# iorx65n register map
Registers are 8-bit, access not given, no defined reset value unless marked. A register's access mark holds for its fields unless they carry their own. Addresses are absolute; registers are grouped by the start of their names; [hi:lo] are bit positions.

## SFR (part 6 of 7)
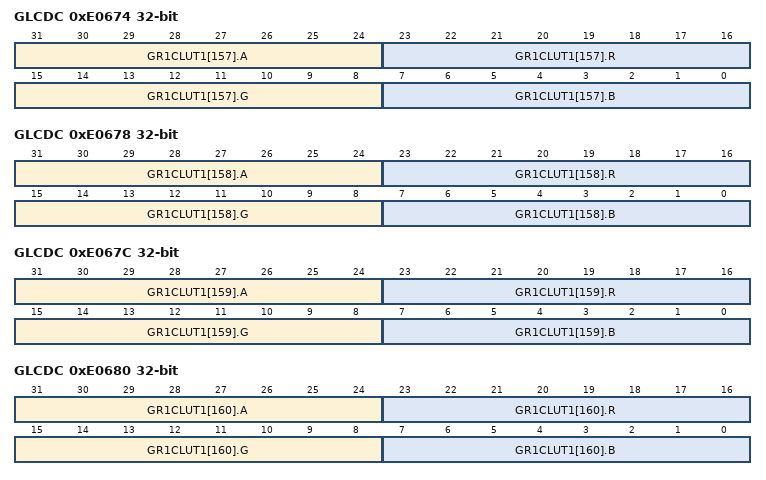
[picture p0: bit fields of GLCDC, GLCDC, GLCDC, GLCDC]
0xE0674 GLCDC 32-bit
  [31:24] GR1CLUT1[157].A, [23:16] GR1CLUT1[157].R, [15:8] GR1CLUT1[157].G, [7:0] GR1CLUT1[157].B
0xE0678 GLCDC 32-bit
  [31:24] GR1CLUT1[158].A, [23:16] GR1CLUT1[158].R, [15:8] GR1CLUT1[158].G, [7:0] GR1CLUT1[158].B
0xE067C GLCDC 32-bit
  [31:24] GR1CLUT1[159].A, [23:16] GR1CLUT1[159].R, [15:8] GR1CLUT1[159].G, [7:0] GR1CLUT1[159].B
0xE0680 GLCDC 32-bit
  [31:24] GR1CLUT1[160].A, [23:16] GR1CLUT1[160].R, [15:8] GR1CLUT1[160].G, [7:0] GR1CLUT1[160].B
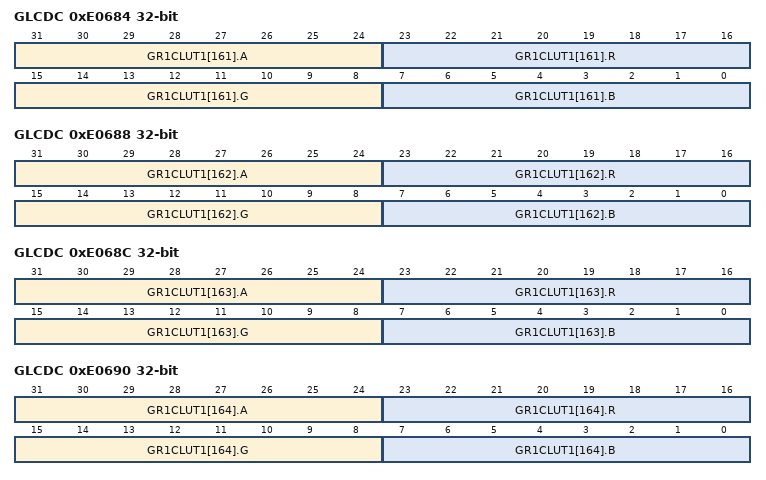
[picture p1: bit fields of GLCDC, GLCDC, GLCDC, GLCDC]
0xE0684 GLCDC 32-bit
  [31:24] GR1CLUT1[161].A, [23:16] GR1CLUT1[161].R, [15:8] GR1CLUT1[161].G, [7:0] GR1CLUT1[161].B
0xE0688 GLCDC 32-bit
  [31:24] GR1CLUT1[162].A, [23:16] GR1CLUT1[162].R, [15:8] GR1CLUT1[162].G, [7:0] GR1CLUT1[162].B
0xE068C GLCDC 32-bit
  [31:24] GR1CLUT1[163].A, [23:16] GR1CLUT1[163].R, [15:8] GR1CLUT1[163].G, [7:0] GR1CLUT1[163].B
0xE0690 GLCDC 32-bit
  [31:24] GR1CLUT1[164].A, [23:16] GR1CLUT1[164].R, [15:8] GR1CLUT1[164].G, [7:0] GR1CLUT1[164].B
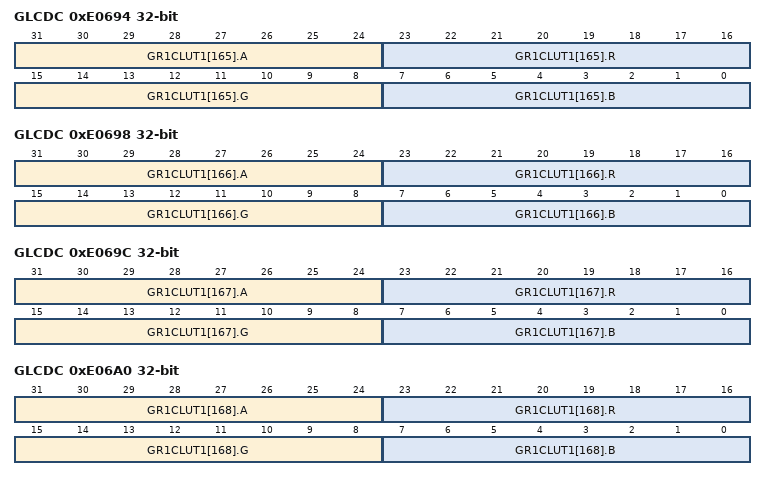
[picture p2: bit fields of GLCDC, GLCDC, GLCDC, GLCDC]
0xE0694 GLCDC 32-bit
  [31:24] GR1CLUT1[165].A, [23:16] GR1CLUT1[165].R, [15:8] GR1CLUT1[165].G, [7:0] GR1CLUT1[165].B
0xE0698 GLCDC 32-bit
  [31:24] GR1CLUT1[166].A, [23:16] GR1CLUT1[166].R, [15:8] GR1CLUT1[166].G, [7:0] GR1CLUT1[166].B
0xE069C GLCDC 32-bit
  [31:24] GR1CLUT1[167].A, [23:16] GR1CLUT1[167].R, [15:8] GR1CLUT1[167].G, [7:0] GR1CLUT1[167].B
0xE06A0 GLCDC 32-bit
  [31:24] GR1CLUT1[168].A, [23:16] GR1CLUT1[168].R, [15:8] GR1CLUT1[168].G, [7:0] GR1CLUT1[168].B
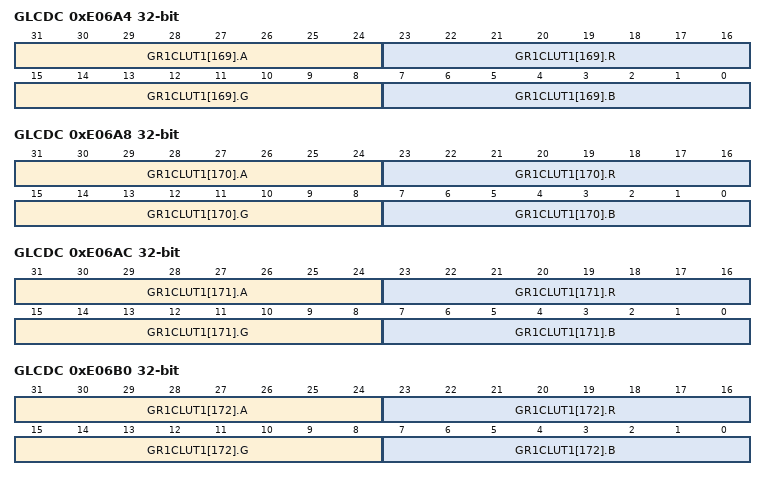
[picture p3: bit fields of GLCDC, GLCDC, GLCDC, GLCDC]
0xE06A4 GLCDC 32-bit
  [31:24] GR1CLUT1[169].A, [23:16] GR1CLUT1[169].R, [15:8] GR1CLUT1[169].G, [7:0] GR1CLUT1[169].B
0xE06A8 GLCDC 32-bit
  [31:24] GR1CLUT1[170].A, [23:16] GR1CLUT1[170].R, [15:8] GR1CLUT1[170].G, [7:0] GR1CLUT1[170].B
0xE06AC GLCDC 32-bit
  [31:24] GR1CLUT1[171].A, [23:16] GR1CLUT1[171].R, [15:8] GR1CLUT1[171].G, [7:0] GR1CLUT1[171].B
0xE06B0 GLCDC 32-bit
  [31:24] GR1CLUT1[172].A, [23:16] GR1CLUT1[172].R, [15:8] GR1CLUT1[172].G, [7:0] GR1CLUT1[172].B
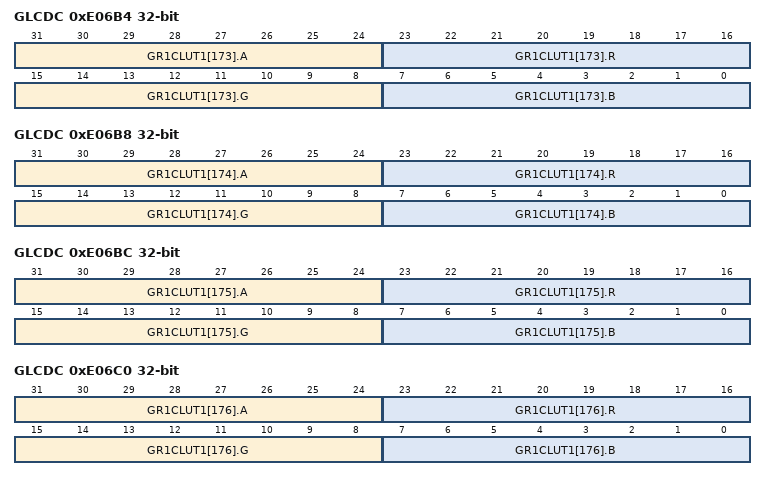
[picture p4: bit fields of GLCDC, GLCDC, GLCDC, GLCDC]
0xE06B4 GLCDC 32-bit
  [31:24] GR1CLUT1[173].A, [23:16] GR1CLUT1[173].R, [15:8] GR1CLUT1[173].G, [7:0] GR1CLUT1[173].B
0xE06B8 GLCDC 32-bit
  [31:24] GR1CLUT1[174].A, [23:16] GR1CLUT1[174].R, [15:8] GR1CLUT1[174].G, [7:0] GR1CLUT1[174].B
0xE06BC GLCDC 32-bit
  [31:24] GR1CLUT1[175].A, [23:16] GR1CLUT1[175].R, [15:8] GR1CLUT1[175].G, [7:0] GR1CLUT1[175].B
0xE06C0 GLCDC 32-bit
  [31:24] GR1CLUT1[176].A, [23:16] GR1CLUT1[176].R, [15:8] GR1CLUT1[176].G, [7:0] GR1CLUT1[176].B
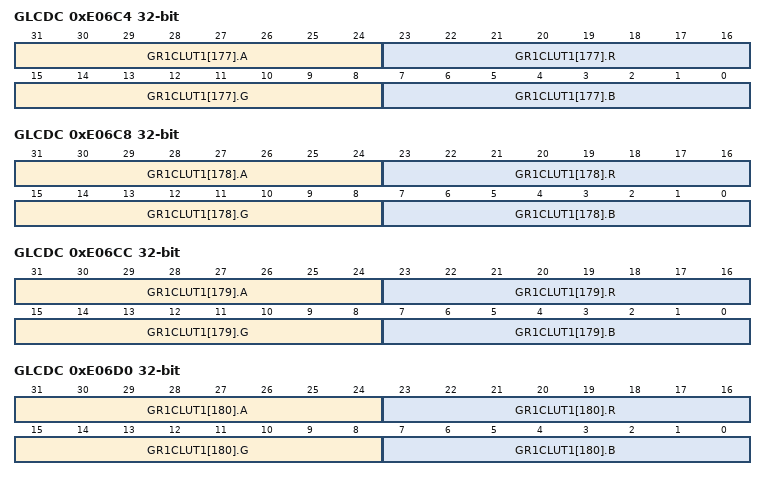
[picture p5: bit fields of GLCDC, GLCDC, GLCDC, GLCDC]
0xE06C4 GLCDC 32-bit
  [31:24] GR1CLUT1[177].A, [23:16] GR1CLUT1[177].R, [15:8] GR1CLUT1[177].G, [7:0] GR1CLUT1[177].B
0xE06C8 GLCDC 32-bit
  [31:24] GR1CLUT1[178].A, [23:16] GR1CLUT1[178].R, [15:8] GR1CLUT1[178].G, [7:0] GR1CLUT1[178].B
0xE06CC GLCDC 32-bit
  [31:24] GR1CLUT1[179].A, [23:16] GR1CLUT1[179].R, [15:8] GR1CLUT1[179].G, [7:0] GR1CLUT1[179].B
0xE06D0 GLCDC 32-bit
  [31:24] GR1CLUT1[180].A, [23:16] GR1CLUT1[180].R, [15:8] GR1CLUT1[180].G, [7:0] GR1CLUT1[180].B
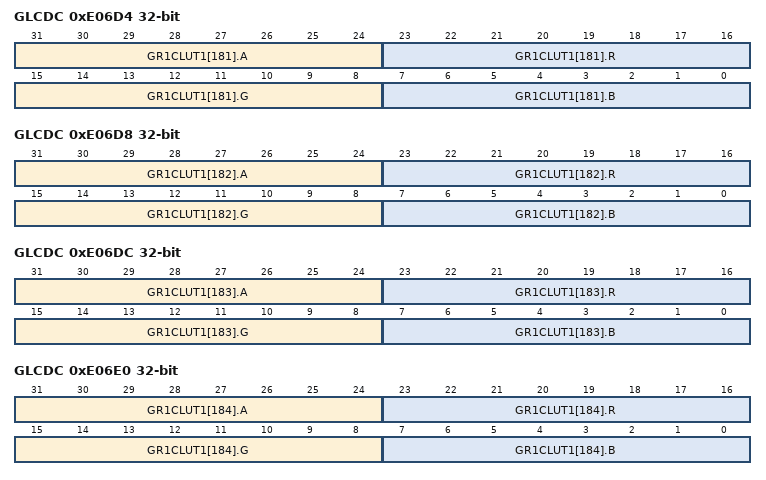
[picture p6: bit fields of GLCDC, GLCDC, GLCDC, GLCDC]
0xE06D4 GLCDC 32-bit
  [31:24] GR1CLUT1[181].A, [23:16] GR1CLUT1[181].R, [15:8] GR1CLUT1[181].G, [7:0] GR1CLUT1[181].B
0xE06D8 GLCDC 32-bit
  [31:24] GR1CLUT1[182].A, [23:16] GR1CLUT1[182].R, [15:8] GR1CLUT1[182].G, [7:0] GR1CLUT1[182].B
0xE06DC GLCDC 32-bit
  [31:24] GR1CLUT1[183].A, [23:16] GR1CLUT1[183].R, [15:8] GR1CLUT1[183].G, [7:0] GR1CLUT1[183].B
0xE06E0 GLCDC 32-bit
  [31:24] GR1CLUT1[184].A, [23:16] GR1CLUT1[184].R, [15:8] GR1CLUT1[184].G, [7:0] GR1CLUT1[184].B
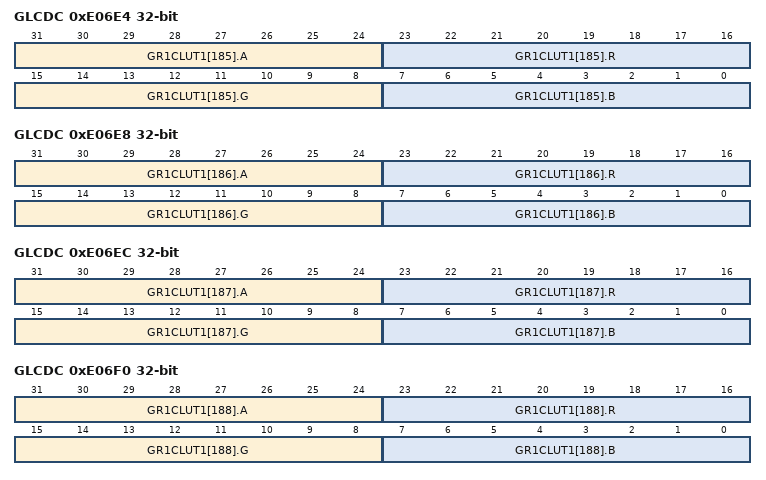
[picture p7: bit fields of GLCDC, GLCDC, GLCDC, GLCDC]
0xE06E4 GLCDC 32-bit
  [31:24] GR1CLUT1[185].A, [23:16] GR1CLUT1[185].R, [15:8] GR1CLUT1[185].G, [7:0] GR1CLUT1[185].B
0xE06E8 GLCDC 32-bit
  [31:24] GR1CLUT1[186].A, [23:16] GR1CLUT1[186].R, [15:8] GR1CLUT1[186].G, [7:0] GR1CLUT1[186].B
0xE06EC GLCDC 32-bit
  [31:24] GR1CLUT1[187].A, [23:16] GR1CLUT1[187].R, [15:8] GR1CLUT1[187].G, [7:0] GR1CLUT1[187].B
0xE06F0 GLCDC 32-bit
  [31:24] GR1CLUT1[188].A, [23:16] GR1CLUT1[188].R, [15:8] GR1CLUT1[188].G, [7:0] GR1CLUT1[188].B
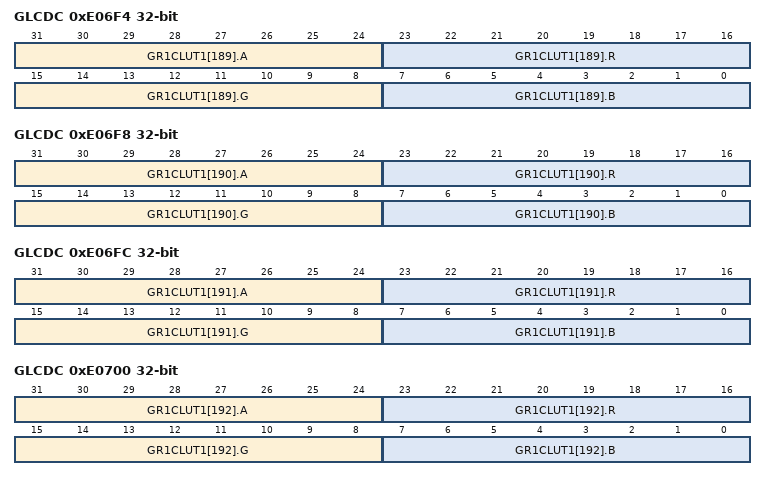
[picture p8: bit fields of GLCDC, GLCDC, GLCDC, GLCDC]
0xE06F4 GLCDC 32-bit
  [31:24] GR1CLUT1[189].A, [23:16] GR1CLUT1[189].R, [15:8] GR1CLUT1[189].G, [7:0] GR1CLUT1[189].B
0xE06F8 GLCDC 32-bit
  [31:24] GR1CLUT1[190].A, [23:16] GR1CLUT1[190].R, [15:8] GR1CLUT1[190].G, [7:0] GR1CLUT1[190].B
0xE06FC GLCDC 32-bit
  [31:24] GR1CLUT1[191].A, [23:16] GR1CLUT1[191].R, [15:8] GR1CLUT1[191].G, [7:0] GR1CLUT1[191].B
0xE0700 GLCDC 32-bit
  [31:24] GR1CLUT1[192].A, [23:16] GR1CLUT1[192].R, [15:8] GR1CLUT1[192].G, [7:0] GR1CLUT1[192].B
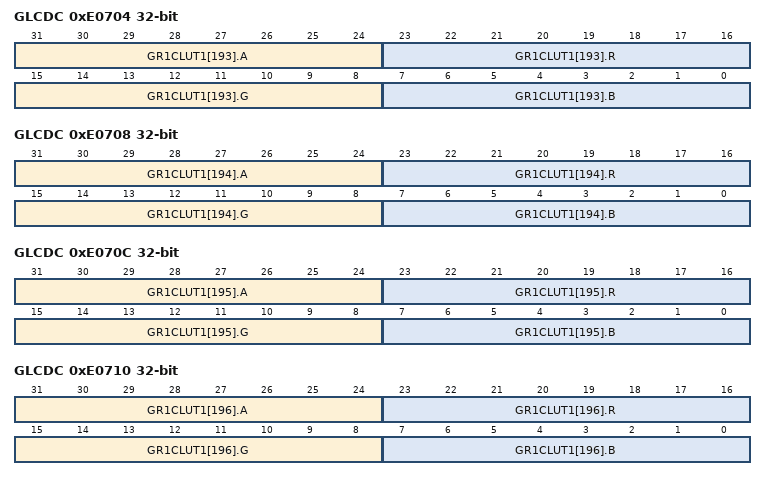
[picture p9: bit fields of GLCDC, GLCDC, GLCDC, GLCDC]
0xE0704 GLCDC 32-bit
  [31:24] GR1CLUT1[193].A, [23:16] GR1CLUT1[193].R, [15:8] GR1CLUT1[193].G, [7:0] GR1CLUT1[193].B
0xE0708 GLCDC 32-bit
  [31:24] GR1CLUT1[194].A, [23:16] GR1CLUT1[194].R, [15:8] GR1CLUT1[194].G, [7:0] GR1CLUT1[194].B
0xE070C GLCDC 32-bit
  [31:24] GR1CLUT1[195].A, [23:16] GR1CLUT1[195].R, [15:8] GR1CLUT1[195].G, [7:0] GR1CLUT1[195].B
0xE0710 GLCDC 32-bit
  [31:24] GR1CLUT1[196].A, [23:16] GR1CLUT1[196].R, [15:8] GR1CLUT1[196].G, [7:0] GR1CLUT1[196].B
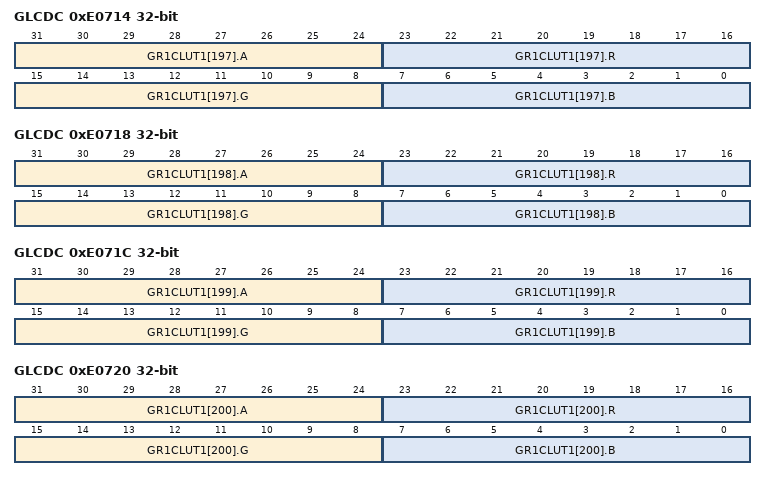
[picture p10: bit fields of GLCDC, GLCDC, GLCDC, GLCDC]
0xE0714 GLCDC 32-bit
  [31:24] GR1CLUT1[197].A, [23:16] GR1CLUT1[197].R, [15:8] GR1CLUT1[197].G, [7:0] GR1CLUT1[197].B
0xE0718 GLCDC 32-bit
  [31:24] GR1CLUT1[198].A, [23:16] GR1CLUT1[198].R, [15:8] GR1CLUT1[198].G, [7:0] GR1CLUT1[198].B
0xE071C GLCDC 32-bit
  [31:24] GR1CLUT1[199].A, [23:16] GR1CLUT1[199].R, [15:8] GR1CLUT1[199].G, [7:0] GR1CLUT1[199].B
0xE0720 GLCDC 32-bit
  [31:24] GR1CLUT1[200].A, [23:16] GR1CLUT1[200].R, [15:8] GR1CLUT1[200].G, [7:0] GR1CLUT1[200].B
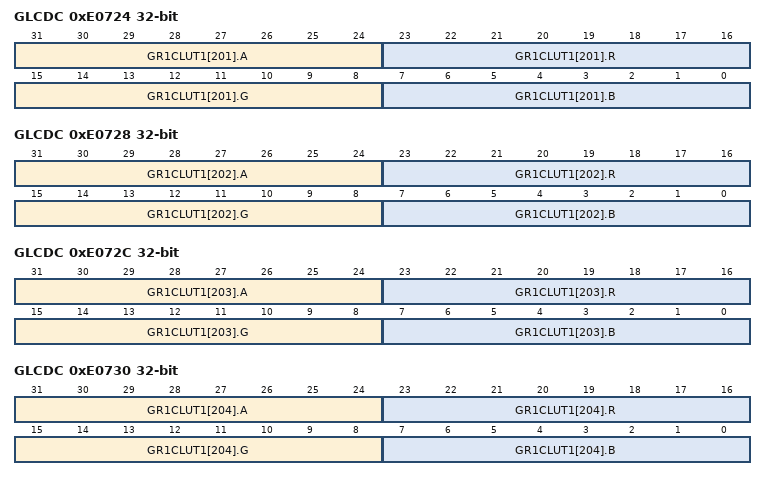
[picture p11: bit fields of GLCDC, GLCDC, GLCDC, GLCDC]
0xE0724 GLCDC 32-bit
  [31:24] GR1CLUT1[201].A, [23:16] GR1CLUT1[201].R, [15:8] GR1CLUT1[201].G, [7:0] GR1CLUT1[201].B
0xE0728 GLCDC 32-bit
  [31:24] GR1CLUT1[202].A, [23:16] GR1CLUT1[202].R, [15:8] GR1CLUT1[202].G, [7:0] GR1CLUT1[202].B
0xE072C GLCDC 32-bit
  [31:24] GR1CLUT1[203].A, [23:16] GR1CLUT1[203].R, [15:8] GR1CLUT1[203].G, [7:0] GR1CLUT1[203].B
0xE0730 GLCDC 32-bit
  [31:24] GR1CLUT1[204].A, [23:16] GR1CLUT1[204].R, [15:8] GR1CLUT1[204].G, [7:0] GR1CLUT1[204].B
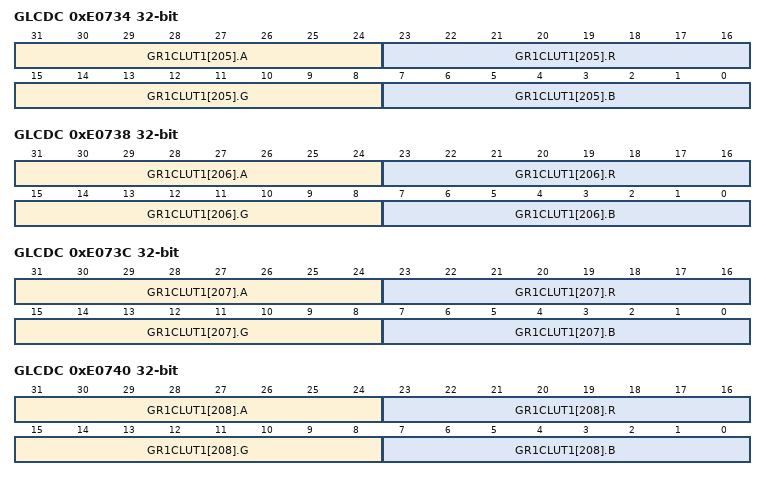
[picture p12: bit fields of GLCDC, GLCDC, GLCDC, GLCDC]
0xE0734 GLCDC 32-bit
  [31:24] GR1CLUT1[205].A, [23:16] GR1CLUT1[205].R, [15:8] GR1CLUT1[205].G, [7:0] GR1CLUT1[205].B
0xE0738 GLCDC 32-bit
  [31:24] GR1CLUT1[206].A, [23:16] GR1CLUT1[206].R, [15:8] GR1CLUT1[206].G, [7:0] GR1CLUT1[206].B
0xE073C GLCDC 32-bit
  [31:24] GR1CLUT1[207].A, [23:16] GR1CLUT1[207].R, [15:8] GR1CLUT1[207].G, [7:0] GR1CLUT1[207].B
0xE0740 GLCDC 32-bit
  [31:24] GR1CLUT1[208].A, [23:16] GR1CLUT1[208].R, [15:8] GR1CLUT1[208].G, [7:0] GR1CLUT1[208].B
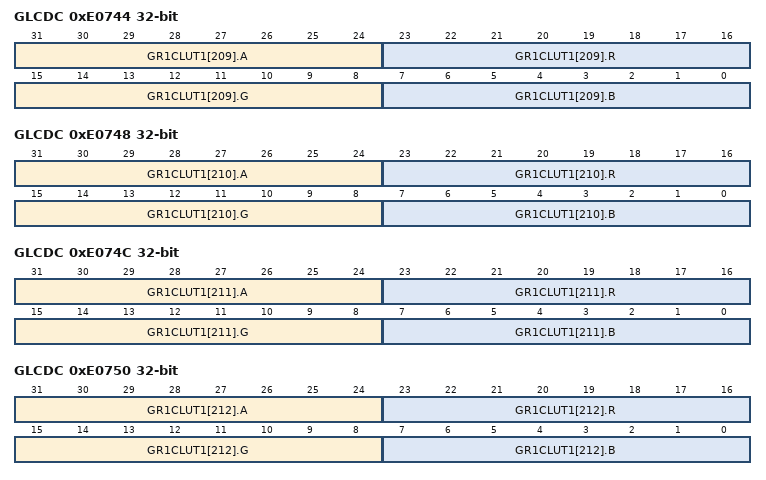
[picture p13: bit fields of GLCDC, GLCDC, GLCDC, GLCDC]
0xE0744 GLCDC 32-bit
  [31:24] GR1CLUT1[209].A, [23:16] GR1CLUT1[209].R, [15:8] GR1CLUT1[209].G, [7:0] GR1CLUT1[209].B
0xE0748 GLCDC 32-bit
  [31:24] GR1CLUT1[210].A, [23:16] GR1CLUT1[210].R, [15:8] GR1CLUT1[210].G, [7:0] GR1CLUT1[210].B
0xE074C GLCDC 32-bit
  [31:24] GR1CLUT1[211].A, [23:16] GR1CLUT1[211].R, [15:8] GR1CLUT1[211].G, [7:0] GR1CLUT1[211].B
0xE0750 GLCDC 32-bit
  [31:24] GR1CLUT1[212].A, [23:16] GR1CLUT1[212].R, [15:8] GR1CLUT1[212].G, [7:0] GR1CLUT1[212].B
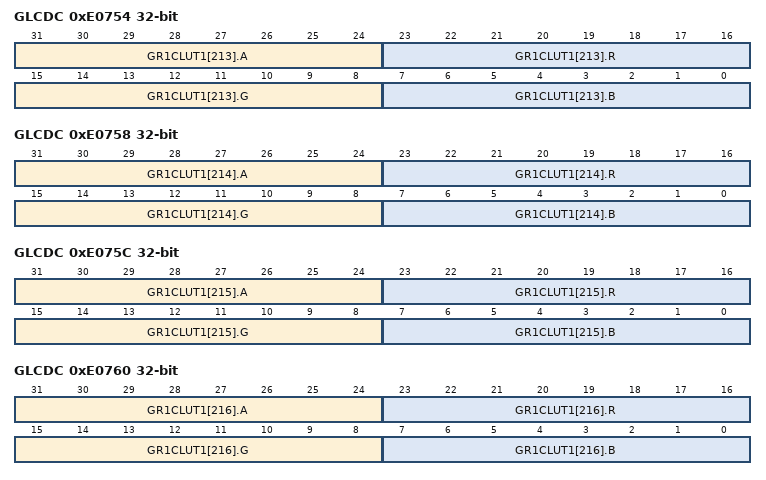
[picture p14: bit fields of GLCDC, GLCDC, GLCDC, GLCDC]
0xE0754 GLCDC 32-bit
  [31:24] GR1CLUT1[213].A, [23:16] GR1CLUT1[213].R, [15:8] GR1CLUT1[213].G, [7:0] GR1CLUT1[213].B
0xE0758 GLCDC 32-bit
  [31:24] GR1CLUT1[214].A, [23:16] GR1CLUT1[214].R, [15:8] GR1CLUT1[214].G, [7:0] GR1CLUT1[214].B
0xE075C GLCDC 32-bit
  [31:24] GR1CLUT1[215].A, [23:16] GR1CLUT1[215].R, [15:8] GR1CLUT1[215].G, [7:0] GR1CLUT1[215].B
0xE0760 GLCDC 32-bit
  [31:24] GR1CLUT1[216].A, [23:16] GR1CLUT1[216].R, [15:8] GR1CLUT1[216].G, [7:0] GR1CLUT1[216].B
0xE0764 GLCDC 32-bit
  [31:24] GR1CLUT1[217].A, [23:16] GR1CLUT1[217].R, [15:8] GR1CLUT1[217].G, [7:0] GR1CLUT1[217].B
0xE0768 GLCDC 32-bit
  [31:24] GR1CLUT1[218].A, [23:16] GR1CLUT1[218].R, [15:8] GR1CLUT1[218].G, [7:0] GR1CLUT1[218].B
0xE076C GLCDC 32-bit
  [31:24] GR1CLUT1[219].A, [23:16] GR1CLUT1[219].R, [15:8] GR1CLUT1[219].G, [7:0] GR1CLUT1[219].B
0xE0770 GLCDC 32-bit
  [31:24] GR1CLUT1[220].A, [23:16] GR1CLUT1[220].R, [15:8] GR1CLUT1[220].G, [7:0] GR1CLUT1[220].B
0xE0774 GLCDC 32-bit
  [31:24] GR1CLUT1[221].A, [23:16] GR1CLUT1[221].R, [15:8] GR1CLUT1[221].G, [7:0] GR1CLUT1[221].B
0xE0778 GLCDC 32-bit
  [31:24] GR1CLUT1[222].A, [23:16] GR1CLUT1[222].R, [15:8] GR1CLUT1[222].G, [7:0] GR1CLUT1[222].B
0xE077C GLCDC 32-bit
  [31:24] GR1CLUT1[223].A, [23:16] GR1CLUT1[223].R, [15:8] GR1CLUT1[223].G, [7:0] GR1CLUT1[223].B
0xE0780 GLCDC 32-bit
  [31:24] GR1CLUT1[224].A, [23:16] GR1CLUT1[224].R, [15:8] GR1CLUT1[224].G, [7:0] GR1CLUT1[224].B
0xE0784 GLCDC 32-bit
  [31:24] GR1CLUT1[225].A, [23:16] GR1CLUT1[225].R, [15:8] GR1CLUT1[225].G, [7:0] GR1CLUT1[225].B
0xE0788 GLCDC 32-bit
  [31:24] GR1CLUT1[226].A, [23:16] GR1CLUT1[226].R, [15:8] GR1CLUT1[226].G, [7:0] GR1CLUT1[226].B
0xE078C GLCDC 32-bit
  [31:24] GR1CLUT1[227].A, [23:16] GR1CLUT1[227].R, [15:8] GR1CLUT1[227].G, [7:0] GR1CLUT1[227].B
0xE0790 GLCDC 32-bit
  [31:24] GR1CLUT1[228].A, [23:16] GR1CLUT1[228].R, [15:8] GR1CLUT1[228].G, [7:0] GR1CLUT1[228].B
0xE0794 GLCDC 32-bit
  [31:24] GR1CLUT1[229].A, [23:16] GR1CLUT1[229].R, [15:8] GR1CLUT1[229].G, [7:0] GR1CLUT1[229].B
0xE0798 GLCDC 32-bit
  [31:24] GR1CLUT1[230].A, [23:16] GR1CLUT1[230].R, [15:8] GR1CLUT1[230].G, [7:0] GR1CLUT1[230].B
0xE079C GLCDC 32-bit
  [31:24] GR1CLUT1[231].A, [23:16] GR1CLUT1[231].R, [15:8] GR1CLUT1[231].G, [7:0] GR1CLUT1[231].B
0xE07A0 GLCDC 32-bit
  [31:24] GR1CLUT1[232].A, [23:16] GR1CLUT1[232].R, [15:8] GR1CLUT1[232].G, [7:0] GR1CLUT1[232].B
0xE07A4 GLCDC 32-bit
  [31:24] GR1CLUT1[233].A, [23:16] GR1CLUT1[233].R, [15:8] GR1CLUT1[233].G, [7:0] GR1CLUT1[233].B
0xE07A8 GLCDC 32-bit
  [31:24] GR1CLUT1[234].A, [23:16] GR1CLUT1[234].R, [15:8] GR1CLUT1[234].G, [7:0] GR1CLUT1[234].B
0xE07AC GLCDC 32-bit
  [31:24] GR1CLUT1[235].A, [23:16] GR1CLUT1[235].R, [15:8] GR1CLUT1[235].G, [7:0] GR1CLUT1[235].B
0xE07B0 GLCDC 32-bit
  [31:24] GR1CLUT1[236].A, [23:16] GR1CLUT1[236].R, [15:8] GR1CLUT1[236].G, [7:0] GR1CLUT1[236].B
0xE07B4 GLCDC 32-bit
  [31:24] GR1CLUT1[237].A, [23:16] GR1CLUT1[237].R, [15:8] GR1CLUT1[237].G, [7:0] GR1CLUT1[237].B
0xE07B8 GLCDC 32-bit
  [31:24] GR1CLUT1[238].A, [23:16] GR1CLUT1[238].R, [15:8] GR1CLUT1[238].G, [7:0] GR1CLUT1[238].B
0xE07BC GLCDC 32-bit
  [31:24] GR1CLUT1[239].A, [23:16] GR1CLUT1[239].R, [15:8] GR1CLUT1[239].G, [7:0] GR1CLUT1[239].B
0xE07C0 GLCDC 32-bit
  [31:24] GR1CLUT1[240].A, [23:16] GR1CLUT1[240].R, [15:8] GR1CLUT1[240].G, [7:0] GR1CLUT1[240].B
0xE07C4 GLCDC 32-bit
  [31:24] GR1CLUT1[241].A, [23:16] GR1CLUT1[241].R, [15:8] GR1CLUT1[241].G, [7:0] GR1CLUT1[241].B
0xE07C8 GLCDC 32-bit
  [31:24] GR1CLUT1[242].A, [23:16] GR1CLUT1[242].R, [15:8] GR1CLUT1[242].G, [7:0] GR1CLUT1[242].B
0xE07CC GLCDC 32-bit
  [31:24] GR1CLUT1[243].A, [23:16] GR1CLUT1[243].R, [15:8] GR1CLUT1[243].G, [7:0] GR1CLUT1[243].B
0xE07D0 GLCDC 32-bit
  [31:24] GR1CLUT1[244].A, [23:16] GR1CLUT1[244].R, [15:8] GR1CLUT1[244].G, [7:0] GR1CLUT1[244].B
0xE07D4 GLCDC 32-bit
  [31:24] GR1CLUT1[245].A, [23:16] GR1CLUT1[245].R, [15:8] GR1CLUT1[245].G, [7:0] GR1CLUT1[245].B
0xE07D8 GLCDC 32-bit
  [31:24] GR1CLUT1[246].A, [23:16] GR1CLUT1[246].R, [15:8] GR1CLUT1[246].G, [7:0] GR1CLUT1[246].B
0xE07DC GLCDC 32-bit
  [31:24] GR1CLUT1[247].A, [23:16] GR1CLUT1[247].R, [15:8] GR1CLUT1[247].G, [7:0] GR1CLUT1[247].B
0xE07E0 GLCDC 32-bit
  [31:24] GR1CLUT1[248].A, [23:16] GR1CLUT1[248].R, [15:8] GR1CLUT1[248].G, [7:0] GR1CLUT1[248].B
0xE07E4 GLCDC 32-bit
  [31:24] GR1CLUT1[249].A, [23:16] GR1CLUT1[249].R, [15:8] GR1CLUT1[249].G, [7:0] GR1CLUT1[249].B
0xE07E8 GLCDC 32-bit
  [31:24] GR1CLUT1[250].A, [23:16] GR1CLUT1[250].R, [15:8] GR1CLUT1[250].G, [7:0] GR1CLUT1[250].B
0xE07EC GLCDC 32-bit
  [31:24] GR1CLUT1[251].A, [23:16] GR1CLUT1[251].R, [15:8] GR1CLUT1[251].G, [7:0] GR1CLUT1[251].B
0xE07F0 GLCDC 32-bit
  [31:24] GR1CLUT1[252].A, [23:16] GR1CLUT1[252].R, [15:8] GR1CLUT1[252].G, [7:0] GR1CLUT1[252].B
0xE07F4 GLCDC 32-bit
  [31:24] GR1CLUT1[253].A, [23:16] GR1CLUT1[253].R, [15:8] GR1CLUT1[253].G, [7:0] GR1CLUT1[253].B
0xE07F8 GLCDC 32-bit
  [31:24] GR1CLUT1[254].A, [23:16] GR1CLUT1[254].R, [15:8] GR1CLUT1[254].G, [7:0] GR1CLUT1[254].B
0xE07FC GLCDC 32-bit
  [31:24] GR1CLUT1[255].A, [23:16] GR1CLUT1[255].R, [15:8] GR1CLUT1[255].G, [7:0] GR1CLUT1[255].B
0xE0800 GLCDC 32-bit
  [31:24] GR2CLUT0[0].A, [23:16] GR2CLUT0[0].R, [15:8] GR2CLUT0[0].G, [7:0] GR2CLUT0[0].B
0xE0804 GLCDC 32-bit
  [31:24] GR2CLUT0[1].A, [23:16] GR2CLUT0[1].R, [15:8] GR2CLUT0[1].G, [7:0] GR2CLUT0[1].B
0xE0808 GLCDC 32-bit
  [31:24] GR2CLUT0[2].A, [23:16] GR2CLUT0[2].R, [15:8] GR2CLUT0[2].G, [7:0] GR2CLUT0[2].B
0xE080C GLCDC 32-bit
  [31:24] GR2CLUT0[3].A, [23:16] GR2CLUT0[3].R, [15:8] GR2CLUT0[3].G, [7:0] GR2CLUT0[3].B
0xE0810 GLCDC 32-bit
  [31:24] GR2CLUT0[4].A, [23:16] GR2CLUT0[4].R, [15:8] GR2CLUT0[4].G, [7:0] GR2CLUT0[4].B
0xE0814 GLCDC 32-bit
  [31:24] GR2CLUT0[5].A, [23:16] GR2CLUT0[5].R, [15:8] GR2CLUT0[5].G, [7:0] GR2CLUT0[5].B
0xE0818 GLCDC 32-bit
  [31:24] GR2CLUT0[6].A, [23:16] GR2CLUT0[6].R, [15:8] GR2CLUT0[6].G, [7:0] GR2CLUT0[6].B
0xE081C GLCDC 32-bit
  [31:24] GR2CLUT0[7].A, [23:16] GR2CLUT0[7].R, [15:8] GR2CLUT0[7].G, [7:0] GR2CLUT0[7].B
0xE0820 GLCDC 32-bit
  [31:24] GR2CLUT0[8].A, [23:16] GR2CLUT0[8].R, [15:8] GR2CLUT0[8].G, [7:0] GR2CLUT0[8].B
0xE0824 GLCDC 32-bit
  [31:24] GR2CLUT0[9].A, [23:16] GR2CLUT0[9].R, [15:8] GR2CLUT0[9].G, [7:0] GR2CLUT0[9].B
0xE0828 GLCDC 32-bit
  [31:24] GR2CLUT0[10].A, [23:16] GR2CLUT0[10].R, [15:8] GR2CLUT0[10].G, [7:0] GR2CLUT0[10].B
0xE082C GLCDC 32-bit
  [31:24] GR2CLUT0[11].A, [23:16] GR2CLUT0[11].R, [15:8] GR2CLUT0[11].G, [7:0] GR2CLUT0[11].B
0xE0830 GLCDC 32-bit
  [31:24] GR2CLUT0[12].A, [23:16] GR2CLUT0[12].R, [15:8] GR2CLUT0[12].G, [7:0] GR2CLUT0[12].B
0xE0834 GLCDC 32-bit
  [31:24] GR2CLUT0[13].A, [23:16] GR2CLUT0[13].R, [15:8] GR2CLUT0[13].G, [7:0] GR2CLUT0[13].B
0xE0838 GLCDC 32-bit
  [31:24] GR2CLUT0[14].A, [23:16] GR2CLUT0[14].R, [15:8] GR2CLUT0[14].G, [7:0] GR2CLUT0[14].B
0xE083C GLCDC 32-bit
  [31:24] GR2CLUT0[15].A, [23:16] GR2CLUT0[15].R, [15:8] GR2CLUT0[15].G, [7:0] GR2CLUT0[15].B
0xE0840 GLCDC 32-bit
  [31:24] GR2CLUT0[16].A, [23:16] GR2CLUT0[16].R, [15:8] GR2CLUT0[16].G, [7:0] GR2CLUT0[16].B
0xE0844 GLCDC 32-bit
  [31:24] GR2CLUT0[17].A, [23:16] GR2CLUT0[17].R, [15:8] GR2CLUT0[17].G, [7:0] GR2CLUT0[17].B
0xE0848 GLCDC 32-bit
  [31:24] GR2CLUT0[18].A, [23:16] GR2CLUT0[18].R, [15:8] GR2CLUT0[18].G, [7:0] GR2CLUT0[18].B
0xE084C GLCDC 32-bit
  [31:24] GR2CLUT0[19].A, [23:16] GR2CLUT0[19].R, [15:8] GR2CLUT0[19].G, [7:0] GR2CLUT0[19].B
0xE0850 GLCDC 32-bit
  [31:24] GR2CLUT0[20].A, [23:16] GR2CLUT0[20].R, [15:8] GR2CLUT0[20].G, [7:0] GR2CLUT0[20].B
0xE0854 GLCDC 32-bit
  [31:24] GR2CLUT0[21].A, [23:16] GR2CLUT0[21].R, [15:8] GR2CLUT0[21].G, [7:0] GR2CLUT0[21].B
0xE0858 GLCDC 32-bit
  [31:24] GR2CLUT0[22].A, [23:16] GR2CLUT0[22].R, [15:8] GR2CLUT0[22].G, [7:0] GR2CLUT0[22].B
0xE085C GLCDC 32-bit
  [31:24] GR2CLUT0[23].A, [23:16] GR2CLUT0[23].R, [15:8] GR2CLUT0[23].G, [7:0] GR2CLUT0[23].B
0xE0860 GLCDC 32-bit
  [31:24] GR2CLUT0[24].A, [23:16] GR2CLUT0[24].R, [15:8] GR2CLUT0[24].G, [7:0] GR2CLUT0[24].B
0xE0864 GLCDC 32-bit
  [31:24] GR2CLUT0[25].A, [23:16] GR2CLUT0[25].R, [15:8] GR2CLUT0[25].G, [7:0] GR2CLUT0[25].B
0xE0868 GLCDC 32-bit
  [31:24] GR2CLUT0[26].A, [23:16] GR2CLUT0[26].R, [15:8] GR2CLUT0[26].G, [7:0] GR2CLUT0[26].B
0xE086C GLCDC 32-bit
  [31:24] GR2CLUT0[27].A, [23:16] GR2CLUT0[27].R, [15:8] GR2CLUT0[27].G, [7:0] GR2CLUT0[27].B
0xE0870 GLCDC 32-bit
  [31:24] GR2CLUT0[28].A, [23:16] GR2CLUT0[28].R, [15:8] GR2CLUT0[28].G, [7:0] GR2CLUT0[28].B
0xE0874 GLCDC 32-bit
  [31:24] GR2CLUT0[29].A, [23:16] GR2CLUT0[29].R, [15:8] GR2CLUT0[29].G, [7:0] GR2CLUT0[29].B
0xE0878 GLCDC 32-bit
  [31:24] GR2CLUT0[30].A, [23:16] GR2CLUT0[30].R, [15:8] GR2CLUT0[30].G, [7:0] GR2CLUT0[30].B
0xE087C GLCDC 32-bit
  [31:24] GR2CLUT0[31].A, [23:16] GR2CLUT0[31].R, [15:8] GR2CLUT0[31].G, [7:0] GR2CLUT0[31].B
0xE0880 GLCDC 32-bit
  [31:24] GR2CLUT0[32].A, [23:16] GR2CLUT0[32].R, [15:8] GR2CLUT0[32].G, [7:0] GR2CLUT0[32].B
0xE0884 GLCDC 32-bit
  [31:24] GR2CLUT0[33].A, [23:16] GR2CLUT0[33].R, [15:8] GR2CLUT0[33].G, [7:0] GR2CLUT0[33].B
0xE0888 GLCDC 32-bit
  [31:24] GR2CLUT0[34].A, [23:16] GR2CLUT0[34].R, [15:8] GR2CLUT0[34].G, [7:0] GR2CLUT0[34].B
0xE088C GLCDC 32-bit
  [31:24] GR2CLUT0[35].A, [23:16] GR2CLUT0[35].R, [15:8] GR2CLUT0[35].G, [7:0] GR2CLUT0[35].B
0xE0890 GLCDC 32-bit
  [31:24] GR2CLUT0[36].A, [23:16] GR2CLUT0[36].R, [15:8] GR2CLUT0[36].G, [7:0] GR2CLUT0[36].B
0xE0894 GLCDC 32-bit
  [31:24] GR2CLUT0[37].A, [23:16] GR2CLUT0[37].R, [15:8] GR2CLUT0[37].G, [7:0] GR2CLUT0[37].B
0xE0898 GLCDC 32-bit
  [31:24] GR2CLUT0[38].A, [23:16] GR2CLUT0[38].R, [15:8] GR2CLUT0[38].G, [7:0] GR2CLUT0[38].B
0xE089C GLCDC 32-bit
  [31:24] GR2CLUT0[39].A, [23:16] GR2CLUT0[39].R, [15:8] GR2CLUT0[39].G, [7:0] GR2CLUT0[39].B
0xE08A0 GLCDC 32-bit
  [31:24] GR2CLUT0[40].A, [23:16] GR2CLUT0[40].R, [15:8] GR2CLUT0[40].G, [7:0] GR2CLUT0[40].B
0xE08A4 GLCDC 32-bit
  [31:24] GR2CLUT0[41].A, [23:16] GR2CLUT0[41].R, [15:8] GR2CLUT0[41].G, [7:0] GR2CLUT0[41].B
0xE08A8 GLCDC 32-bit
  [31:24] GR2CLUT0[42].A, [23:16] GR2CLUT0[42].R, [15:8] GR2CLUT0[42].G, [7:0] GR2CLUT0[42].B
0xE08AC GLCDC 32-bit
  [31:24] GR2CLUT0[43].A, [23:16] GR2CLUT0[43].R, [15:8] GR2CLUT0[43].G, [7:0] GR2CLUT0[43].B
0xE08B0 GLCDC 32-bit
  [31:24] GR2CLUT0[44].A, [23:16] GR2CLUT0[44].R, [15:8] GR2CLUT0[44].G, [7:0] GR2CLUT0[44].B
0xE08B4 GLCDC 32-bit
  [31:24] GR2CLUT0[45].A, [23:16] GR2CLUT0[45].R, [15:8] GR2CLUT0[45].G, [7:0] GR2CLUT0[45].B
0xE08B8 GLCDC 32-bit
  [31:24] GR2CLUT0[46].A, [23:16] GR2CLUT0[46].R, [15:8] GR2CLUT0[46].G, [7:0] GR2CLUT0[46].B
0xE08BC GLCDC 32-bit
  [31:24] GR2CLUT0[47].A, [23:16] GR2CLUT0[47].R, [15:8] GR2CLUT0[47].G, [7:0] GR2CLUT0[47].B
0xE08C0 GLCDC 32-bit
  [31:24] GR2CLUT0[48].A, [23:16] GR2CLUT0[48].R, [15:8] GR2CLUT0[48].G, [7:0] GR2CLUT0[48].B
0xE08C4 GLCDC 32-bit
  [31:24] GR2CLUT0[49].A, [23:16] GR2CLUT0[49].R, [15:8] GR2CLUT0[49].G, [7:0] GR2CLUT0[49].B
0xE08C8 GLCDC 32-bit
  [31:24] GR2CLUT0[50].A, [23:16] GR2CLUT0[50].R, [15:8] GR2CLUT0[50].G, [7:0] GR2CLUT0[50].B
0xE08CC GLCDC 32-bit
  [31:24] GR2CLUT0[51].A, [23:16] GR2CLUT0[51].R, [15:8] GR2CLUT0[51].G, [7:0] GR2CLUT0[51].B
0xE08D0 GLCDC 32-bit
  [31:24] GR2CLUT0[52].A, [23:16] GR2CLUT0[52].R, [15:8] GR2CLUT0[52].G, [7:0] GR2CLUT0[52].B
0xE08D4 GLCDC 32-bit
  [31:24] GR2CLUT0[53].A, [23:16] GR2CLUT0[53].R, [15:8] GR2CLUT0[53].G, [7:0] GR2CLUT0[53].B
0xE08D8 GLCDC 32-bit
  [31:24] GR2CLUT0[54].A, [23:16] GR2CLUT0[54].R, [15:8] GR2CLUT0[54].G, [7:0] GR2CLUT0[54].B
0xE08DC GLCDC 32-bit
  [31:24] GR2CLUT0[55].A, [23:16] GR2CLUT0[55].R, [15:8] GR2CLUT0[55].G, [7:0] GR2CLUT0[55].B
0xE08E0 GLCDC 32-bit
  [31:24] GR2CLUT0[56].A, [23:16] GR2CLUT0[56].R, [15:8] GR2CLUT0[56].G, [7:0] GR2CLUT0[56].B
0xE08E4 GLCDC 32-bit
  [31:24] GR2CLUT0[57].A, [23:16] GR2CLUT0[57].R, [15:8] GR2CLUT0[57].G, [7:0] GR2CLUT0[57].B
0xE08E8 GLCDC 32-bit
  [31:24] GR2CLUT0[58].A, [23:16] GR2CLUT0[58].R, [15:8] GR2CLUT0[58].G, [7:0] GR2CLUT0[58].B
0xE08EC GLCDC 32-bit
  [31:24] GR2CLUT0[59].A, [23:16] GR2CLUT0[59].R, [15:8] GR2CLUT0[59].G, [7:0] GR2CLUT0[59].B
0xE08F0 GLCDC 32-bit
  [31:24] GR2CLUT0[60].A, [23:16] GR2CLUT0[60].R, [15:8] GR2CLUT0[60].G, [7:0] GR2CLUT0[60].B
0xE08F4 GLCDC 32-bit
  [31:24] GR2CLUT0[61].A, [23:16] GR2CLUT0[61].R, [15:8] GR2CLUT0[61].G, [7:0] GR2CLUT0[61].B
0xE08F8 GLCDC 32-bit
  [31:24] GR2CLUT0[62].A, [23:16] GR2CLUT0[62].R, [15:8] GR2CLUT0[62].G, [7:0] GR2CLUT0[62].B
0xE08FC GLCDC 32-bit
  [31:24] GR2CLUT0[63].A, [23:16] GR2CLUT0[63].R, [15:8] GR2CLUT0[63].G, [7:0] GR2CLUT0[63].B
0xE0900 GLCDC 32-bit
  [31:24] GR2CLUT0[64].A, [23:16] GR2CLUT0[64].R, [15:8] GR2CLUT0[64].G, [7:0] GR2CLUT0[64].B
0xE0904 GLCDC 32-bit
  [31:24] GR2CLUT0[65].A, [23:16] GR2CLUT0[65].R, [15:8] GR2CLUT0[65].G, [7:0] GR2CLUT0[65].B
0xE0908 GLCDC 32-bit
  [31:24] GR2CLUT0[66].A, [23:16] GR2CLUT0[66].R, [15:8] GR2CLUT0[66].G, [7:0] GR2CLUT0[66].B
0xE090C GLCDC 32-bit
  [31:24] GR2CLUT0[67].A, [23:16] GR2CLUT0[67].R, [15:8] GR2CLUT0[67].G, [7:0] GR2CLUT0[67].B
0xE0910 GLCDC 32-bit
  [31:24] GR2CLUT0[68].A, [23:16] GR2CLUT0[68].R, [15:8] GR2CLUT0[68].G, [7:0] GR2CLUT0[68].B
0xE0914 GLCDC 32-bit
  [31:24] GR2CLUT0[69].A, [23:16] GR2CLUT0[69].R, [15:8] GR2CLUT0[69].G, [7:0] GR2CLUT0[69].B
0xE0918 GLCDC 32-bit
  [31:24] GR2CLUT0[70].A, [23:16] GR2CLUT0[70].R, [15:8] GR2CLUT0[70].G, [7:0] GR2CLUT0[70].B
0xE091C GLCDC 32-bit
  [31:24] GR2CLUT0[71].A, [23:16] GR2CLUT0[71].R, [15:8] GR2CLUT0[71].G, [7:0] GR2CLUT0[71].B
0xE0920 GLCDC 32-bit
  [31:24] GR2CLUT0[72].A, [23:16] GR2CLUT0[72].R, [15:8] GR2CLUT0[72].G, [7:0] GR2CLUT0[72].B
0xE0924 GLCDC 32-bit
  [31:24] GR2CLUT0[73].A, [23:16] GR2CLUT0[73].R, [15:8] GR2CLUT0[73].G, [7:0] GR2CLUT0[73].B
0xE0928 GLCDC 32-bit
  [31:24] GR2CLUT0[74].A, [23:16] GR2CLUT0[74].R, [15:8] GR2CLUT0[74].G, [7:0] GR2CLUT0[74].B
0xE092C GLCDC 32-bit
  [31:24] GR2CLUT0[75].A, [23:16] GR2CLUT0[75].R, [15:8] GR2CLUT0[75].G, [7:0] GR2CLUT0[75].B
0xE0930 GLCDC 32-bit
  [31:24] GR2CLUT0[76].A, [23:16] GR2CLUT0[76].R, [15:8] GR2CLUT0[76].G, [7:0] GR2CLUT0[76].B
0xE0934 GLCDC 32-bit
  [31:24] GR2CLUT0[77].A, [23:16] GR2CLUT0[77].R, [15:8] GR2CLUT0[77].G, [7:0] GR2CLUT0[77].B
0xE0938 GLCDC 32-bit
  [31:24] GR2CLUT0[78].A, [23:16] GR2CLUT0[78].R, [15:8] GR2CLUT0[78].G, [7:0] GR2CLUT0[78].B
0xE093C GLCDC 32-bit
  [31:24] GR2CLUT0[79].A, [23:16] GR2CLUT0[79].R, [15:8] GR2CLUT0[79].G, [7:0] GR2CLUT0[79].B
0xE0940 GLCDC 32-bit
  [31:24] GR2CLUT0[80].A, [23:16] GR2CLUT0[80].R, [15:8] GR2CLUT0[80].G, [7:0] GR2CLUT0[80].B
0xE0944 GLCDC 32-bit
  [31:24] GR2CLUT0[81].A, [23:16] GR2CLUT0[81].R, [15:8] GR2CLUT0[81].G, [7:0] GR2CLUT0[81].B
0xE0948 GLCDC 32-bit
  [31:24] GR2CLUT0[82].A, [23:16] GR2CLUT0[82].R, [15:8] GR2CLUT0[82].G, [7:0] GR2CLUT0[82].B
0xE094C GLCDC 32-bit
  [31:24] GR2CLUT0[83].A, [23:16] GR2CLUT0[83].R, [15:8] GR2CLUT0[83].G, [7:0] GR2CLUT0[83].B
0xE0950 GLCDC 32-bit
  [31:24] GR2CLUT0[84].A, [23:16] GR2CLUT0[84].R, [15:8] GR2CLUT0[84].G, [7:0] GR2CLUT0[84].B
0xE0954 GLCDC 32-bit
  [31:24] GR2CLUT0[85].A, [23:16] GR2CLUT0[85].R, [15:8] GR2CLUT0[85].G, [7:0] GR2CLUT0[85].B
0xE0958 GLCDC 32-bit
  [31:24] GR2CLUT0[86].A, [23:16] GR2CLUT0[86].R, [15:8] GR2CLUT0[86].G, [7:0] GR2CLUT0[86].B
0xE095C GLCDC 32-bit
  [31:24] GR2CLUT0[87].A, [23:16] GR2CLUT0[87].R, [15:8] GR2CLUT0[87].G, [7:0] GR2CLUT0[87].B
0xE0960 GLCDC 32-bit
  [31:24] GR2CLUT0[88].A, [23:16] GR2CLUT0[88].R, [15:8] GR2CLUT0[88].G, [7:0] GR2CLUT0[88].B
0xE0964 GLCDC 32-bit
  [31:24] GR2CLUT0[89].A, [23:16] GR2CLUT0[89].R, [15:8] GR2CLUT0[89].G, [7:0] GR2CLUT0[89].B
0xE0968 GLCDC 32-bit
  [31:24] GR2CLUT0[90].A, [23:16] GR2CLUT0[90].R, [15:8] GR2CLUT0[90].G, [7:0] GR2CLUT0[90].B
0xE096C GLCDC 32-bit
  [31:24] GR2CLUT0[91].A, [23:16] GR2CLUT0[91].R, [15:8] GR2CLUT0[91].G, [7:0] GR2CLUT0[91].B
0xE0970 GLCDC 32-bit
  [31:24] GR2CLUT0[92].A, [23:16] GR2CLUT0[92].R, [15:8] GR2CLUT0[92].G, [7:0] GR2CLUT0[92].B
0xE0974 GLCDC 32-bit
  [31:24] GR2CLUT0[93].A, [23:16] GR2CLUT0[93].R, [15:8] GR2CLUT0[93].G, [7:0] GR2CLUT0[93].B
0xE0978 GLCDC 32-bit
  [31:24] GR2CLUT0[94].A, [23:16] GR2CLUT0[94].R, [15:8] GR2CLUT0[94].G, [7:0] GR2CLUT0[94].B
0xE097C GLCDC 32-bit
  [31:24] GR2CLUT0[95].A, [23:16] GR2CLUT0[95].R, [15:8] GR2CLUT0[95].G, [7:0] GR2CLUT0[95].B
0xE0980 GLCDC 32-bit
  [31:24] GR2CLUT0[96].A, [23:16] GR2CLUT0[96].R, [15:8] GR2CLUT0[96].G, [7:0] GR2CLUT0[96].B
0xE0984 GLCDC 32-bit
  [31:24] GR2CLUT0[97].A, [23:16] GR2CLUT0[97].R, [15:8] GR2CLUT0[97].G, [7:0] GR2CLUT0[97].B
0xE0988 GLCDC 32-bit
  [31:24] GR2CLUT0[98].A, [23:16] GR2CLUT0[98].R, [15:8] GR2CLUT0[98].G, [7:0] GR2CLUT0[98].B
0xE098C GLCDC 32-bit
  [31:24] GR2CLUT0[99].A, [23:16] GR2CLUT0[99].R, [15:8] GR2CLUT0[99].G, [7:0] GR2CLUT0[99].B
0xE0990 GLCDC 32-bit
  [31:24] GR2CLUT0[100].A, [23:16] GR2CLUT0[100].R, [15:8] GR2CLUT0[100].G, [7:0] GR2CLUT0[100].B
0xE0994 GLCDC 32-bit
  [31:24] GR2CLUT0[101].A, [23:16] GR2CLUT0[101].R, [15:8] GR2CLUT0[101].G, [7:0] GR2CLUT0[101].B
0xE0998 GLCDC 32-bit
  [31:24] GR2CLUT0[102].A, [23:16] GR2CLUT0[102].R, [15:8] GR2CLUT0[102].G, [7:0] GR2CLUT0[102].B
0xE099C GLCDC 32-bit
  [31:24] GR2CLUT0[103].A, [23:16] GR2CLUT0[103].R, [15:8] GR2CLUT0[103].G, [7:0] GR2CLUT0[103].B
0xE09A0 GLCDC 32-bit
  [31:24] GR2CLUT0[104].A, [23:16] GR2CLUT0[104].R, [15:8] GR2CLUT0[104].G, [7:0] GR2CLUT0[104].B
0xE09A4 GLCDC 32-bit
  [31:24] GR2CLUT0[105].A, [23:16] GR2CLUT0[105].R, [15:8] GR2CLUT0[105].G, [7:0] GR2CLUT0[105].B
0xE09A8 GLCDC 32-bit
  [31:24] GR2CLUT0[106].A, [23:16] GR2CLUT0[106].R, [15:8] GR2CLUT0[106].G, [7:0] GR2CLUT0[106].B
0xE09AC GLCDC 32-bit
  [31:24] GR2CLUT0[107].A, [23:16] GR2CLUT0[107].R, [15:8] GR2CLUT0[107].G, [7:0] GR2CLUT0[107].B
0xE09B0 GLCDC 32-bit
  [31:24] GR2CLUT0[108].A, [23:16] GR2CLUT0[108].R, [15:8] GR2CLUT0[108].G, [7:0] GR2CLUT0[108].B
0xE09B4 GLCDC 32-bit
  [31:24] GR2CLUT0[109].A, [23:16] GR2CLUT0[109].R, [15:8] GR2CLUT0[109].G, [7:0] GR2CLUT0[109].B
0xE09B8 GLCDC 32-bit
  [31:24] GR2CLUT0[110].A, [23:16] GR2CLUT0[110].R, [15:8] GR2CLUT0[110].G, [7:0] GR2CLUT0[110].B
0xE09BC GLCDC 32-bit
  [31:24] GR2CLUT0[111].A, [23:16] GR2CLUT0[111].R, [15:8] GR2CLUT0[111].G, [7:0] GR2CLUT0[111].B
0xE09C0 GLCDC 32-bit
  [31:24] GR2CLUT0[112].A, [23:16] GR2CLUT0[112].R, [15:8] GR2CLUT0[112].G, [7:0] GR2CLUT0[112].B
0xE09C4 GLCDC 32-bit
  [31:24] GR2CLUT0[113].A, [23:16] GR2CLUT0[113].R, [15:8] GR2CLUT0[113].G, [7:0] GR2CLUT0[113].B
0xE09C8 GLCDC 32-bit
  [31:24] GR2CLUT0[114].A, [23:16] GR2CLUT0[114].R, [15:8] GR2CLUT0[114].G, [7:0] GR2CLUT0[114].B
0xE09CC GLCDC 32-bit
  [31:24] GR2CLUT0[115].A, [23:16] GR2CLUT0[115].R, [15:8] GR2CLUT0[115].G, [7:0] GR2CLUT0[115].B
0xE09D0 GLCDC 32-bit
  [31:24] GR2CLUT0[116].A, [23:16] GR2CLUT0[116].R, [15:8] GR2CLUT0[116].G, [7:0] GR2CLUT0[116].B
0xE09D4 GLCDC 32-bit
  [31:24] GR2CLUT0[117].A, [23:16] GR2CLUT0[117].R, [15:8] GR2CLUT0[117].G, [7:0] GR2CLUT0[117].B
0xE09D8 GLCDC 32-bit
  [31:24] GR2CLUT0[118].A, [23:16] GR2CLUT0[118].R, [15:8] GR2CLUT0[118].G, [7:0] GR2CLUT0[118].B
0xE09DC GLCDC 32-bit
  [31:24] GR2CLUT0[119].A, [23:16] GR2CLUT0[119].R, [15:8] GR2CLUT0[119].G, [7:0] GR2CLUT0[119].B
0xE09E0 GLCDC 32-bit
  [31:24] GR2CLUT0[120].A, [23:16] GR2CLUT0[120].R, [15:8] GR2CLUT0[120].G, [7:0] GR2CLUT0[120].B
0xE09E4 GLCDC 32-bit
  [31:24] GR2CLUT0[121].A, [23:16] GR2CLUT0[121].R, [15:8] GR2CLUT0[121].G, [7:0] GR2CLUT0[121].B
0xE09E8 GLCDC 32-bit
  [31:24] GR2CLUT0[122].A, [23:16] GR2CLUT0[122].R, [15:8] GR2CLUT0[122].G, [7:0] GR2CLUT0[122].B
0xE09EC GLCDC 32-bit
  [31:24] GR2CLUT0[123].A, [23:16] GR2CLUT0[123].R, [15:8] GR2CLUT0[123].G, [7:0] GR2CLUT0[123].B
0xE09F0 GLCDC 32-bit
  [31:24] GR2CLUT0[124].A, [23:16] GR2CLUT0[124].R, [15:8] GR2CLUT0[124].G, [7:0] GR2CLUT0[124].B
0xE09F4 GLCDC 32-bit
  [31:24] GR2CLUT0[125].A, [23:16] GR2CLUT0[125].R, [15:8] GR2CLUT0[125].G, [7:0] GR2CLUT0[125].B
0xE09F8 GLCDC 32-bit
  [31:24] GR2CLUT0[126].A, [23:16] GR2CLUT0[126].R, [15:8] GR2CLUT0[126].G, [7:0] GR2CLUT0[126].B
0xE09FC GLCDC 32-bit
  [31:24] GR2CLUT0[127].A, [23:16] GR2CLUT0[127].R, [15:8] GR2CLUT0[127].G, [7:0] GR2CLUT0[127].B
0xE0A00 GLCDC 32-bit
  [31:24] GR2CLUT0[128].A, [23:16] GR2CLUT0[128].R, [15:8] GR2CLUT0[128].G, [7:0] GR2CLUT0[128].B
0xE0A04 GLCDC 32-bit
  [31:24] GR2CLUT0[129].A, [23:16] GR2CLUT0[129].R, [15:8] GR2CLUT0[129].G, [7:0] GR2CLUT0[129].B
0xE0A08 GLCDC 32-bit
  [31:24] GR2CLUT0[130].A, [23:16] GR2CLUT0[130].R, [15:8] GR2CLUT0[130].G, [7:0] GR2CLUT0[130].B
0xE0A0C GLCDC 32-bit
  [31:24] GR2CLUT0[131].A, [23:16] GR2CLUT0[131].R, [15:8] GR2CLUT0[131].G, [7:0] GR2CLUT0[131].B
0xE0A10 GLCDC 32-bit
  [31:24] GR2CLUT0[132].A, [23:16] GR2CLUT0[132].R, [15:8] GR2CLUT0[132].G, [7:0] GR2CLUT0[132].B
0xE0A14 GLCDC 32-bit
  [31:24] GR2CLUT0[133].A, [23:16] GR2CLUT0[133].R, [15:8] GR2CLUT0[133].G, [7:0] GR2CLUT0[133].B
0xE0A18 GLCDC 32-bit
  [31:24] GR2CLUT0[134].A, [23:16] GR2CLUT0[134].R, [15:8] GR2CLUT0[134].G, [7:0] GR2CLUT0[134].B
0xE0A1C GLCDC 32-bit
  [31:24] GR2CLUT0[135].A, [23:16] GR2CLUT0[135].R, [15:8] GR2CLUT0[135].G, [7:0] GR2CLUT0[135].B
0xE0A20 GLCDC 32-bit
  [31:24] GR2CLUT0[136].A, [23:16] GR2CLUT0[136].R, [15:8] GR2CLUT0[136].G, [7:0] GR2CLUT0[136].B
0xE0A24 GLCDC 32-bit
  [31:24] GR2CLUT0[137].A, [23:16] GR2CLUT0[137].R, [15:8] GR2CLUT0[137].G, [7:0] GR2CLUT0[137].B
0xE0A28 GLCDC 32-bit
  [31:24] GR2CLUT0[138].A, [23:16] GR2CLUT0[138].R, [15:8] GR2CLUT0[138].G, [7:0] GR2CLUT0[138].B
0xE0A2C GLCDC 32-bit
  [31:24] GR2CLUT0[139].A, [23:16] GR2CLUT0[139].R, [15:8] GR2CLUT0[139].G, [7:0] GR2CLUT0[139].B
0xE0A30 GLCDC 32-bit
  [31:24] GR2CLUT0[140].A, [23:16] GR2CLUT0[140].R, [15:8] GR2CLUT0[140].G, [7:0] GR2CLUT0[140].B
0xE0A34 GLCDC 32-bit
  [31:24] GR2CLUT0[141].A, [23:16] GR2CLUT0[141].R, [15:8] GR2CLUT0[141].G, [7:0] GR2CLUT0[141].B
0xE0A38 GLCDC 32-bit
  [31:24] GR2CLUT0[142].A, [23:16] GR2CLUT0[142].R, [15:8] GR2CLUT0[142].G, [7:0] GR2CLUT0[142].B
0xE0A3C GLCDC 32-bit
  [31:24] GR2CLUT0[143].A, [23:16] GR2CLUT0[143].R, [15:8] GR2CLUT0[143].G, [7:0] GR2CLUT0[143].B
0xE0A40 GLCDC 32-bit
  [31:24] GR2CLUT0[144].A, [23:16] GR2CLUT0[144].R, [15:8] GR2CLUT0[144].G, [7:0] GR2CLUT0[144].B
0xE0A44 GLCDC 32-bit
  [31:24] GR2CLUT0[145].A, [23:16] GR2CLUT0[145].R, [15:8] GR2CLUT0[145].G, [7:0] GR2CLUT0[145].B
0xE0A48 GLCDC 32-bit
  [31:24] GR2CLUT0[146].A, [23:16] GR2CLUT0[146].R, [15:8] GR2CLUT0[146].G, [7:0] GR2CLUT0[146].B
0xE0A4C GLCDC 32-bit
  [31:24] GR2CLUT0[147].A, [23:16] GR2CLUT0[147].R, [15:8] GR2CLUT0[147].G, [7:0] GR2CLUT0[147].B
0xE0A50 GLCDC 32-bit
  [31:24] GR2CLUT0[148].A, [23:16] GR2CLUT0[148].R, [15:8] GR2CLUT0[148].G, [7:0] GR2CLUT0[148].B
0xE0A54 GLCDC 32-bit
  [31:24] GR2CLUT0[149].A, [23:16] GR2CLUT0[149].R, [15:8] GR2CLUT0[149].G, [7:0] GR2CLUT0[149].B
0xE0A58 GLCDC 32-bit
  [31:24] GR2CLUT0[150].A, [23:16] GR2CLUT0[150].R, [15:8] GR2CLUT0[150].G, [7:0] GR2CLUT0[150].B
0xE0A5C GLCDC 32-bit
  [31:24] GR2CLUT0[151].A, [23:16] GR2CLUT0[151].R, [15:8] GR2CLUT0[151].G, [7:0] GR2CLUT0[151].B
0xE0A60 GLCDC 32-bit
  [31:24] GR2CLUT0[152].A, [23:16] GR2CLUT0[152].R, [15:8] GR2CLUT0[152].G, [7:0] GR2CLUT0[152].B
0xE0A64 GLCDC 32-bit
  [31:24] GR2CLUT0[153].A, [23:16] GR2CLUT0[153].R, [15:8] GR2CLUT0[153].G, [7:0] GR2CLUT0[153].B
0xE0A68 GLCDC 32-bit
  [31:24] GR2CLUT0[154].A, [23:16] GR2CLUT0[154].R, [15:8] GR2CLUT0[154].G, [7:0] GR2CLUT0[154].B
0xE0A6C GLCDC 32-bit
  [31:24] GR2CLUT0[155].A, [23:16] GR2CLUT0[155].R, [15:8] GR2CLUT0[155].G, [7:0] GR2CLUT0[155].B
0xE0A70 GLCDC 32-bit
  [31:24] GR2CLUT0[156].A, [23:16] GR2CLUT0[156].R, [15:8] GR2CLUT0[156].G, [7:0] GR2CLUT0[156].B
0xE0A74 GLCDC 32-bit
  [31:24] GR2CLUT0[157].A, [23:16] GR2CLUT0[157].R, [15:8] GR2CLUT0[157].G, [7:0] GR2CLUT0[157].B
0xE0A78 GLCDC 32-bit
  [31:24] GR2CLUT0[158].A, [23:16] GR2CLUT0[158].R, [15:8] GR2CLUT0[158].G, [7:0] GR2CLUT0[158].B
0xE0A7C GLCDC 32-bit
  [31:24] GR2CLUT0[159].A, [23:16] GR2CLUT0[159].R, [15:8] GR2CLUT0[159].G, [7:0] GR2CLUT0[159].B
0xE0A80 GLCDC 32-bit
  [31:24] GR2CLUT0[160].A, [23:16] GR2CLUT0[160].R, [15:8] GR2CLUT0[160].G, [7:0] GR2CLUT0[160].B
0xE0A84 GLCDC 32-bit
  [31:24] GR2CLUT0[161].A, [23:16] GR2CLUT0[161].R, [15:8] GR2CLUT0[161].G, [7:0] GR2CLUT0[161].B
0xE0A88 GLCDC 32-bit
  [31:24] GR2CLUT0[162].A, [23:16] GR2CLUT0[162].R, [15:8] GR2CLUT0[162].G, [7:0] GR2CLUT0[162].B
0xE0A8C GLCDC 32-bit
  [31:24] GR2CLUT0[163].A, [23:16] GR2CLUT0[163].R, [15:8] GR2CLUT0[163].G, [7:0] GR2CLUT0[163].B
0xE0A90 GLCDC 32-bit
  [31:24] GR2CLUT0[164].A, [23:16] GR2CLUT0[164].R, [15:8] GR2CLUT0[164].G, [7:0] GR2CLUT0[164].B
0xE0A94 GLCDC 32-bit
  [31:24] GR2CLUT0[165].A, [23:16] GR2CLUT0[165].R, [15:8] GR2CLUT0[165].G, [7:0] GR2CLUT0[165].B
0xE0A98 GLCDC 32-bit
  [31:24] GR2CLUT0[166].A, [23:16] GR2CLUT0[166].R, [15:8] GR2CLUT0[166].G, [7:0] GR2CLUT0[166].B
0xE0A9C GLCDC 32-bit
  [31:24] GR2CLUT0[167].A, [23:16] GR2CLUT0[167].R, [15:8] GR2CLUT0[167].G, [7:0] GR2CLUT0[167].B
0xE0AA0 GLCDC 32-bit
  [31:24] GR2CLUT0[168].A, [23:16] GR2CLUT0[168].R, [15:8] GR2CLUT0[168].G, [7:0] GR2CLUT0[168].B
0xE0AA4 GLCDC 32-bit
  [31:24] GR2CLUT0[169].A, [23:16] GR2CLUT0[169].R, [15:8] GR2CLUT0[169].G, [7:0] GR2CLUT0[169].B
0xE0AA8 GLCDC 32-bit
  [31:24] GR2CLUT0[170].A, [23:16] GR2CLUT0[170].R, [15:8] GR2CLUT0[170].G, [7:0] GR2CLUT0[170].B
0xE0AAC GLCDC 32-bit
  [31:24] GR2CLUT0[171].A, [23:16] GR2CLUT0[171].R, [15:8] GR2CLUT0[171].G, [7:0] GR2CLUT0[171].B
0xE0AB0 GLCDC 32-bit
  [31:24] GR2CLUT0[172].A, [23:16] GR2CLUT0[172].R, [15:8] GR2CLUT0[172].G, [7:0] GR2CLUT0[172].B
0xE0AB4 GLCDC 32-bit
  [31:24] GR2CLUT0[173].A, [23:16] GR2CLUT0[173].R, [15:8] GR2CLUT0[173].G, [7:0] GR2CLUT0[173].B
0xE0AB8 GLCDC 32-bit
  [31:24] GR2CLUT0[174].A, [23:16] GR2CLUT0[174].R, [15:8] GR2CLUT0[174].G, [7:0] GR2CLUT0[174].B
0xE0ABC GLCDC 32-bit
  [31:24] GR2CLUT0[175].A, [23:16] GR2CLUT0[175].R, [15:8] GR2CLUT0[175].G, [7:0] GR2CLUT0[175].B
0xE0AC0 GLCDC 32-bit
  [31:24] GR2CLUT0[176].A, [23:16] GR2CLUT0[176].R, [15:8] GR2CLUT0[176].G, [7:0] GR2CLUT0[176].B
0xE0AC4 GLCDC 32-bit
  [31:24] GR2CLUT0[177].A, [23:16] GR2CLUT0[177].R, [15:8] GR2CLUT0[177].G, [7:0] GR2CLUT0[177].B
0xE0AC8 GLCDC 32-bit
  [31:24] GR2CLUT0[178].A, [23:16] GR2CLUT0[178].R, [15:8] GR2CLUT0[178].G, [7:0] GR2CLUT0[178].B
0xE0ACC GLCDC 32-bit
  [31:24] GR2CLUT0[179].A, [23:16] GR2CLUT0[179].R, [15:8] GR2CLUT0[179].G, [7:0] GR2CLUT0[179].B
0xE0AD0 GLCDC 32-bit
  [31:24] GR2CLUT0[180].A, [23:16] GR2CLUT0[180].R, [15:8] GR2CLUT0[180].G, [7:0] GR2CLUT0[180].B
0xE0AD4 GLCDC 32-bit
  [31:24] GR2CLUT0[181].A, [23:16] GR2CLUT0[181].R, [15:8] GR2CLUT0[181].G, [7:0] GR2CLUT0[181].B
0xE0AD8 GLCDC 32-bit
  [31:24] GR2CLUT0[182].A, [23:16] GR2CLUT0[182].R, [15:8] GR2CLUT0[182].G, [7:0] GR2CLUT0[182].B
0xE0ADC GLCDC 32-bit
  [31:24] GR2CLUT0[183].A, [23:16] GR2CLUT0[183].R, [15:8] GR2CLUT0[183].G, [7:0] GR2CLUT0[183].B
0xE0AE0 GLCDC 32-bit
  [31:24] GR2CLUT0[184].A, [23:16] GR2CLUT0[184].R, [15:8] GR2CLUT0[184].G, [7:0] GR2CLUT0[184].B
0xE0AE4 GLCDC 32-bit
  [31:24] GR2CLUT0[185].A, [23:16] GR2CLUT0[185].R, [15:8] GR2CLUT0[185].G, [7:0] GR2CLUT0[185].B
0xE0AE8 GLCDC 32-bit
  [31:24] GR2CLUT0[186].A, [23:16] GR2CLUT0[186].R, [15:8] GR2CLUT0[186].G, [7:0] GR2CLUT0[186].B
0xE0AEC GLCDC 32-bit
  [31:24] GR2CLUT0[187].A, [23:16] GR2CLUT0[187].R, [15:8] GR2CLUT0[187].G, [7:0] GR2CLUT0[187].B
0xE0AF0 GLCDC 32-bit
  [31:24] GR2CLUT0[188].A, [23:16] GR2CLUT0[188].R, [15:8] GR2CLUT0[188].G, [7:0] GR2CLUT0[188].B
0xE0AF4 GLCDC 32-bit
  [31:24] GR2CLUT0[189].A, [23:16] GR2CLUT0[189].R, [15:8] GR2CLUT0[189].G, [7:0] GR2CLUT0[189].B
0xE0AF8 GLCDC 32-bit
  [31:24] GR2CLUT0[190].A, [23:16] GR2CLUT0[190].R, [15:8] GR2CLUT0[190].G, [7:0] GR2CLUT0[190].B
0xE0AFC GLCDC 32-bit
  [31:24] GR2CLUT0[191].A, [23:16] GR2CLUT0[191].R, [15:8] GR2CLUT0[191].G, [7:0] GR2CLUT0[191].B
0xE0B00 GLCDC 32-bit
  [31:24] GR2CLUT0[192].A, [23:16] GR2CLUT0[192].R, [15:8] GR2CLUT0[192].G, [7:0] GR2CLUT0[192].B
0xE0B04 GLCDC 32-bit
  [31:24] GR2CLUT0[193].A, [23:16] GR2CLUT0[193].R, [15:8] GR2CLUT0[193].G, [7:0] GR2CLUT0[193].B
0xE0B08 GLCDC 32-bit
  [31:24] GR2CLUT0[194].A, [23:16] GR2CLUT0[194].R, [15:8] GR2CLUT0[194].G, [7:0] GR2CLUT0[194].B
0xE0B0C GLCDC 32-bit
  [31:24] GR2CLUT0[195].A, [23:16] GR2CLUT0[195].R, [15:8] GR2CLUT0[195].G, [7:0] GR2CLUT0[195].B
0xE0B10 GLCDC 32-bit
  [31:24] GR2CLUT0[196].A, [23:16] GR2CLUT0[196].R, [15:8] GR2CLUT0[196].G, [7:0] GR2CLUT0[196].B
0xE0B14 GLCDC 32-bit
  [31:24] GR2CLUT0[197].A, [23:16] GR2CLUT0[197].R, [15:8] GR2CLUT0[197].G, [7:0] GR2CLUT0[197].B
0xE0B18 GLCDC 32-bit
  [31:24] GR2CLUT0[198].A, [23:16] GR2CLUT0[198].R, [15:8] GR2CLUT0[198].G, [7:0] GR2CLUT0[198].B
0xE0B1C GLCDC 32-bit
  [31:24] GR2CLUT0[199].A, [23:16] GR2CLUT0[199].R, [15:8] GR2CLUT0[199].G, [7:0] GR2CLUT0[199].B
0xE0B20 GLCDC 32-bit
  [31:24] GR2CLUT0[200].A, [23:16] GR2CLUT0[200].R, [15:8] GR2CLUT0[200].G, [7:0] GR2CLUT0[200].B
0xE0B24 GLCDC 32-bit
  [31:24] GR2CLUT0[201].A, [23:16] GR2CLUT0[201].R, [15:8] GR2CLUT0[201].G, [7:0] GR2CLUT0[201].B
0xE0B28 GLCDC 32-bit
  [31:24] GR2CLUT0[202].A, [23:16] GR2CLUT0[202].R, [15:8] GR2CLUT0[202].G, [7:0] GR2CLUT0[202].B
0xE0B2C GLCDC 32-bit
  [31:24] GR2CLUT0[203].A, [23:16] GR2CLUT0[203].R, [15:8] GR2CLUT0[203].G, [7:0] GR2CLUT0[203].B
0xE0B30 GLCDC 32-bit
  [31:24] GR2CLUT0[204].A, [23:16] GR2CLUT0[204].R, [15:8] GR2CLUT0[204].G, [7:0] GR2CLUT0[204].B
0xE0B34 GLCDC 32-bit
  [31:24] GR2CLUT0[205].A, [23:16] GR2CLUT0[205].R, [15:8] GR2CLUT0[205].G, [7:0] GR2CLUT0[205].B
0xE0B38 GLCDC 32-bit
  [31:24] GR2CLUT0[206].A, [23:16] GR2CLUT0[206].R, [15:8] GR2CLUT0[206].G, [7:0] GR2CLUT0[206].B
0xE0B3C GLCDC 32-bit
  [31:24] GR2CLUT0[207].A, [23:16] GR2CLUT0[207].R, [15:8] GR2CLUT0[207].G, [7:0] GR2CLUT0[207].B
0xE0B40 GLCDC 32-bit
  [31:24] GR2CLUT0[208].A, [23:16] GR2CLUT0[208].R, [15:8] GR2CLUT0[208].G, [7:0] GR2CLUT0[208].B
0xE0B44 GLCDC 32-bit
  [31:24] GR2CLUT0[209].A, [23:16] GR2CLUT0[209].R, [15:8] GR2CLUT0[209].G, [7:0] GR2CLUT0[209].B
0xE0B48 GLCDC 32-bit
  [31:24] GR2CLUT0[210].A, [23:16] GR2CLUT0[210].R, [15:8] GR2CLUT0[210].G, [7:0] GR2CLUT0[210].B
0xE0B4C GLCDC 32-bit
  [31:24] GR2CLUT0[211].A, [23:16] GR2CLUT0[211].R, [15:8] GR2CLUT0[211].G, [7:0] GR2CLUT0[211].B
0xE0B50 GLCDC 32-bit
  [31:24] GR2CLUT0[212].A, [23:16] GR2CLUT0[212].R, [15:8] GR2CLUT0[212].G, [7:0] GR2CLUT0[212].B
0xE0B54 GLCDC 32-bit
  [31:24] GR2CLUT0[213].A, [23:16] GR2CLUT0[213].R, [15:8] GR2CLUT0[213].G, [7:0] GR2CLUT0[213].B
0xE0B58 GLCDC 32-bit
  [31:24] GR2CLUT0[214].A, [23:16] GR2CLUT0[214].R, [15:8] GR2CLUT0[214].G, [7:0] GR2CLUT0[214].B
0xE0B5C GLCDC 32-bit
  [31:24] GR2CLUT0[215].A, [23:16] GR2CLUT0[215].R, [15:8] GR2CLUT0[215].G, [7:0] GR2CLUT0[215].B
0xE0B60 GLCDC 32-bit
  [31:24] GR2CLUT0[216].A, [23:16] GR2CLUT0[216].R, [15:8] GR2CLUT0[216].G, [7:0] GR2CLUT0[216].B
0xE0B64 GLCDC 32-bit
  [31:24] GR2CLUT0[217].A, [23:16] GR2CLUT0[217].R, [15:8] GR2CLUT0[217].G, [7:0] GR2CLUT0[217].B
0xE0B68 GLCDC 32-bit
  [31:24] GR2CLUT0[218].A, [23:16] GR2CLUT0[218].R, [15:8] GR2CLUT0[218].G, [7:0] GR2CLUT0[218].B
0xE0B6C GLCDC 32-bit
  [31:24] GR2CLUT0[219].A, [23:16] GR2CLUT0[219].R, [15:8] GR2CLUT0[219].G, [7:0] GR2CLUT0[219].B
0xE0B70 GLCDC 32-bit
  [31:24] GR2CLUT0[220].A, [23:16] GR2CLUT0[220].R, [15:8] GR2CLUT0[220].G, [7:0] GR2CLUT0[220].B
0xE0B74 GLCDC 32-bit
  [31:24] GR2CLUT0[221].A, [23:16] GR2CLUT0[221].R, [15:8] GR2CLUT0[221].G, [7:0] GR2CLUT0[221].B
0xE0B78 GLCDC 32-bit
  [31:24] GR2CLUT0[222].A, [23:16] GR2CLUT0[222].R, [15:8] GR2CLUT0[222].G, [7:0] GR2CLUT0[222].B
0xE0B7C GLCDC 32-bit
  [31:24] GR2CLUT0[223].A, [23:16] GR2CLUT0[223].R, [15:8] GR2CLUT0[223].G, [7:0] GR2CLUT0[223].B
0xE0B80 GLCDC 32-bit
  [31:24] GR2CLUT0[224].A, [23:16] GR2CLUT0[224].R, [15:8] GR2CLUT0[224].G, [7:0] GR2CLUT0[224].B
0xE0B84 GLCDC 32-bit
  [31:24] GR2CLUT0[225].A, [23:16] GR2CLUT0[225].R, [15:8] GR2CLUT0[225].G, [7:0] GR2CLUT0[225].B
0xE0B88 GLCDC 32-bit
  [31:24] GR2CLUT0[226].A, [23:16] GR2CLUT0[226].R, [15:8] GR2CLUT0[226].G, [7:0] GR2CLUT0[226].B
0xE0B8C GLCDC 32-bit
  [31:24] GR2CLUT0[227].A, [23:16] GR2CLUT0[227].R, [15:8] GR2CLUT0[227].G, [7:0] GR2CLUT0[227].B
0xE0B90 GLCDC 32-bit
  [31:24] GR2CLUT0[228].A, [23:16] GR2CLUT0[228].R, [15:8] GR2CLUT0[228].G, [7:0] GR2CLUT0[228].B
0xE0B94 GLCDC 32-bit
  [31:24] GR2CLUT0[229].A, [23:16] GR2CLUT0[229].R, [15:8] GR2CLUT0[229].G, [7:0] GR2CLUT0[229].B
0xE0B98 GLCDC 32-bit
  [31:24] GR2CLUT0[230].A, [23:16] GR2CLUT0[230].R, [15:8] GR2CLUT0[230].G, [7:0] GR2CLUT0[230].B
0xE0B9C GLCDC 32-bit
  [31:24] GR2CLUT0[231].A, [23:16] GR2CLUT0[231].R, [15:8] GR2CLUT0[231].G, [7:0] GR2CLUT0[231].B
0xE0BA0 GLCDC 32-bit
  [31:24] GR2CLUT0[232].A, [23:16] GR2CLUT0[232].R, [15:8] GR2CLUT0[232].G, [7:0] GR2CLUT0[232].B
0xE0BA4 GLCDC 32-bit
  [31:24] GR2CLUT0[233].A, [23:16] GR2CLUT0[233].R, [15:8] GR2CLUT0[233].G, [7:0] GR2CLUT0[233].B
0xE0BA8 GLCDC 32-bit
  [31:24] GR2CLUT0[234].A, [23:16] GR2CLUT0[234].R, [15:8] GR2CLUT0[234].G, [7:0] GR2CLUT0[234].B
0xE0BAC GLCDC 32-bit
  [31:24] GR2CLUT0[235].A, [23:16] GR2CLUT0[235].R, [15:8] GR2CLUT0[235].G, [7:0] GR2CLUT0[235].B
0xE0BB0 GLCDC 32-bit
  [31:24] GR2CLUT0[236].A, [23:16] GR2CLUT0[236].R, [15:8] GR2CLUT0[236].G, [7:0] GR2CLUT0[236].B
0xE0BB4 GLCDC 32-bit
  [31:24] GR2CLUT0[237].A, [23:16] GR2CLUT0[237].R, [15:8] GR2CLUT0[237].G, [7:0] GR2CLUT0[237].B
0xE0BB8 GLCDC 32-bit
  [31:24] GR2CLUT0[238].A, [23:16] GR2CLUT0[238].R, [15:8] GR2CLUT0[238].G, [7:0] GR2CLUT0[238].B
0xE0BBC GLCDC 32-bit
  [31:24] GR2CLUT0[239].A, [23:16] GR2CLUT0[239].R, [15:8] GR2CLUT0[239].G, [7:0] GR2CLUT0[239].B
0xE0BC0 GLCDC 32-bit
  [31:24] GR2CLUT0[240].A, [23:16] GR2CLUT0[240].R, [15:8] GR2CLUT0[240].G, [7:0] GR2CLUT0[240].B
0xE0BC4 GLCDC 32-bit
  [31:24] GR2CLUT0[241].A, [23:16] GR2CLUT0[241].R, [15:8] GR2CLUT0[241].G, [7:0] GR2CLUT0[241].B
0xE0BC8 GLCDC 32-bit
  [31:24] GR2CLUT0[242].A, [23:16] GR2CLUT0[242].R, [15:8] GR2CLUT0[242].G, [7:0] GR2CLUT0[242].B
0xE0BCC GLCDC 32-bit
  [31:24] GR2CLUT0[243].A, [23:16] GR2CLUT0[243].R, [15:8] GR2CLUT0[243].G, [7:0] GR2CLUT0[243].B
0xE0BD0 GLCDC 32-bit
  [31:24] GR2CLUT0[244].A, [23:16] GR2CLUT0[244].R, [15:8] GR2CLUT0[244].G, [7:0] GR2CLUT0[244].B
0xE0BD4 GLCDC 32-bit
  [31:24] GR2CLUT0[245].A, [23:16] GR2CLUT0[245].R, [15:8] GR2CLUT0[245].G, [7:0] GR2CLUT0[245].B
0xE0BD8 GLCDC 32-bit
  [31:24] GR2CLUT0[246].A, [23:16] GR2CLUT0[246].R, [15:8] GR2CLUT0[246].G, [7:0] GR2CLUT0[246].B
0xE0BDC GLCDC 32-bit
  [31:24] GR2CLUT0[247].A, [23:16] GR2CLUT0[247].R, [15:8] GR2CLUT0[247].G, [7:0] GR2CLUT0[247].B
0xE0BE0 GLCDC 32-bit
  [31:24] GR2CLUT0[248].A, [23:16] GR2CLUT0[248].R, [15:8] GR2CLUT0[248].G, [7:0] GR2CLUT0[248].B
0xE0BE4 GLCDC 32-bit
  [31:24] GR2CLUT0[249].A, [23:16] GR2CLUT0[249].R, [15:8] GR2CLUT0[249].G, [7:0] GR2CLUT0[249].B
0xE0BE8 GLCDC 32-bit
  [31:24] GR2CLUT0[250].A, [23:16] GR2CLUT0[250].R, [15:8] GR2CLUT0[250].G, [7:0] GR2CLUT0[250].B
0xE0BEC GLCDC 32-bit
  [31:24] GR2CLUT0[251].A, [23:16] GR2CLUT0[251].R, [15:8] GR2CLUT0[251].G, [7:0] GR2CLUT0[251].B
